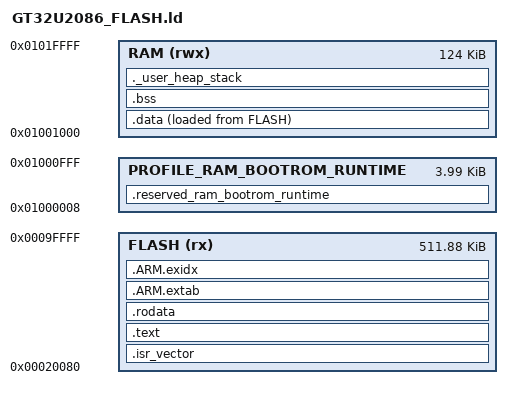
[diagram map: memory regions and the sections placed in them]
/*
 * Auto-generated by mcu-description/tools/generate.py - DO NOT EDIT BY HAND.
 * Source: mcu-description/devices/GT32U2086.yaml
 * Regenerate: python3 mcu-description/tools/generate.py --device GT32U2086 --profile normal
 */

ENTRY(Reset_Handler)

_Min_Heap_Size  = 0x400;  /* required amount of heap  */
_Min_Stack_Size = 0x400;  /* required amount of stack */

MEMORY
{
  PROFILE_RAM_BOOTROM_RUNTIME : ORIGIN = 0x01000008, LENGTH = 0xFF8 /* reserved */
  FLASH (rx)  : ORIGIN = 0x00020080, LENGTH = 0x7FF80
  RAM   (rwx) : ORIGIN = 0x01001000, LENGTH = 0x1F000
}

__profile_ram_bootrom_runtime_start__ = ORIGIN(PROFILE_RAM_BOOTROM_RUNTIME);
__profile_ram_bootrom_runtime_end__ = ORIGIN(PROFILE_RAM_BOOTROM_RUNTIME) + LENGTH(PROFILE_RAM_BOOTROM_RUNTIME);
__profile_ram_bootrom_runtime_size__ = LENGTH(PROFILE_RAM_BOOTROM_RUNTIME);
__vector_table_start__ = ORIGIN(FLASH);
_estack = ORIGIN(RAM) + LENGTH(RAM);

SECTIONS
{
  .reserved_ram_bootrom_runtime (NOLOAD) :
  {
    . = ORIGIN(PROFILE_RAM_BOOTROM_RUNTIME) + LENGTH(PROFILE_RAM_BOOTROM_RUNTIME);
  } > PROFILE_RAM_BOOTROM_RUNTIME

  .isr_vector :
  {
    . = ALIGN(4);
    KEEP(*(.isr_vector))
    . = ALIGN(4);
  } > FLASH

  .text :
  {
    . = ALIGN(4);
    *(.text)
    *(.text*)
    *(.glue_7)
    *(.glue_7t)
    KEEP (*(.init))
    KEEP (*(.fini))
    . = ALIGN(4);
    _etext = .;
  } > FLASH

  .rodata :
  {
    . = ALIGN(4);
    *(.rodata)
    *(.rodata*)
    . = ALIGN(4);
  } > FLASH

  .ARM.extab : { *(.ARM.extab* .gnu.linkonce.armextab.*) } > FLASH
  .ARM.exidx :
  {
    __exidx_start = .;
    *(.ARM.exidx*)
    __exidx_end = .;
  } > FLASH

  _sidata = LOADADDR(.data);

  .data :
  {
    . = ALIGN(4);
    _sdata = .;
    /* Flash operations must be run from RAM in order not to fetch instruction from the Flash array itself
       while the controller is program/erase. */
    *(.ramfunc)
    *(.ramfunc*)
    *(.data)
    *(.data*)
    . = ALIGN(4);
    _edata = .;
  } > RAM AT> FLASH

  . = ALIGN(4);
  .bss :
  {
    _sbss = .;
    *(.bss)
    *(.bss*)
    *(COMMON)
    . = ALIGN(4);
    _ebss = .;
  } > RAM

  ._user_heap_stack :
  {
    . = ALIGN(8);
    PROVIDE ( end = . );
    PROVIDE ( _end = . );
    . = . + _Min_Heap_Size;
    . = . + _Min_Stack_Size;
    . = ALIGN(8);
  } > RAM

  ASSERT(ADDR(.isr_vector) == ORIGIN(FLASH), "vector table moved from configured base")
  /DISCARD/ : { libc.a ( * ) libm.a ( * ) libgcc.a ( * ) }
}
